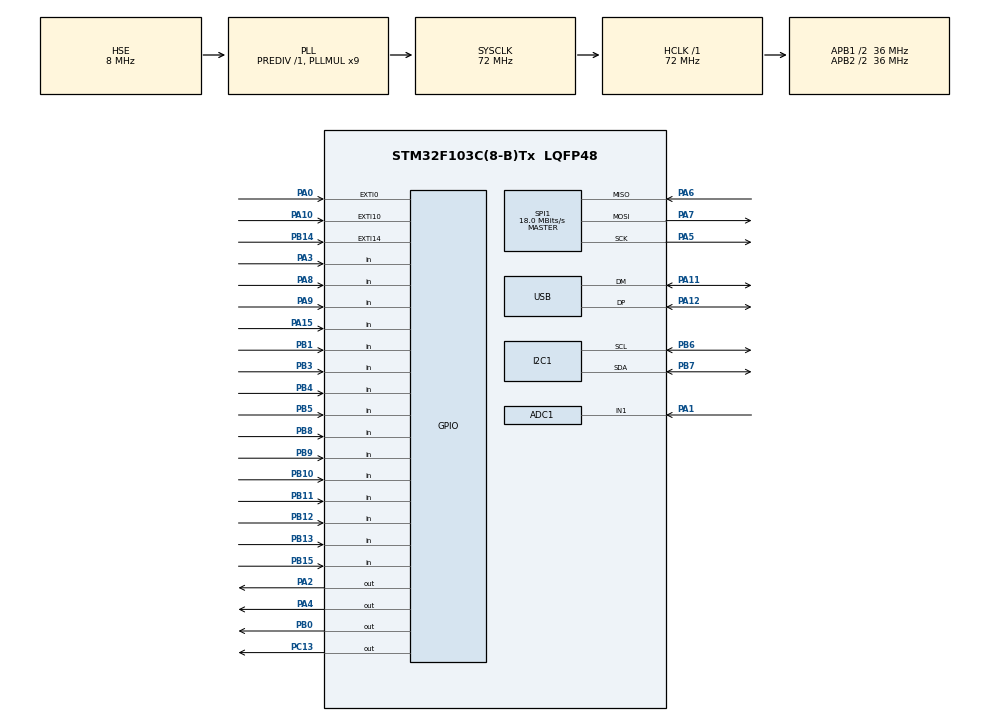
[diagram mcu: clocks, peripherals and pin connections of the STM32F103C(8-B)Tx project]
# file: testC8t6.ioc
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ADC1.Channel-0\#ChannelRegularConversion=ADC_CHANNEL_1
ADC1.NbrOfConversionFlag=1
ADC1.Rank-0\#ChannelRegularConversion=1
ADC1.SamplingTime-0\#ChannelRegularConversion=ADC_SAMPLETIME_1CYCLE_5
ADC1.master=1
Mcu.Family=STM32F1
Mcu.Name=STM32F103C(8-B)Tx
Mcu.Package=LQFP48
NVIC.EXTI15_10_IRQn=true\:9\:0\:true\:false\:true\:true\:true
NVIC.PriorityGroup=NVIC_PRIORITYGROUP_4
NVIC.RCC_IRQn=true\:0\:0\:false\:false\:true\:true\:false
NVIC.TIM3_IRQn=true\:11\:0\:true\:false\:true\:true\:true
NVIC.TIM4_IRQn=true\:0\:0\:false\:false\:true\:true\:true
NVIC.USB_LP_CAN1_RX0_IRQn=true\:0\:0\:false\:false\:true\:false\:true
PA0-WKUP.GPIO_ModeDefaultEXTI=GPIO_MODE_IT_RISING_FALLING
PA0-WKUP.GPIO_PuPd=GPIO_PULLDOWN
PA0-WKUP.Signal=GPXTI0
PA1.Signal=ADCx_IN1
PA10.GPIO_ModeDefaultEXTI=GPIO_MODE_IT_FALLING
PA10.GPIO_PuPd=GPIO_PULLUP
PA10.Signal=GPXTI10
PA11.Mode=Device
PA11.Signal=USB_DM
PA12.Mode=Device
PA12.Signal=USB_DP
PA13.Mode=Serial_Wire
PA13.Signal=SYS_JTMS-SWDIO
PA14.Mode=Serial_Wire
PA14.Signal=SYS_JTCK-SWCLK
PA15.GPIO_PuPd=GPIO_PULLUP
PA15.Signal=GPIO_Input
PA2.Signal=GPIO_Output
PA3.GPIO_PuPd=GPIO_PULLUP
PA3.Signal=GPIO_Input
PA4.GPIO_Speed=GPIO_SPEED_FREQ_HIGH
PA4.Signal=GPIO_Output
PA5.Mode=Full_Duplex_Master
PA5.Signal=SPI1_SCK
PA6.Mode=Full_Duplex_Master
PA6.Signal=SPI1_MISO
PA7.Mode=Full_Duplex_Master
PA7.Signal=SPI1_MOSI
PA8.GPIO_PuPd=GPIO_PULLUP
PA8.Signal=GPIO_Input
PA9.GPIO_PuPd=GPIO_PULLUP
PA9.Signal=GPIO_Input
PB0.Signal=GPIO_Output
PB1.GPIO_PuPd=GPIO_PULLUP
PB1.Signal=GPIO_Input
PB10.GPIO_PuPd=GPIO_PULLUP
PB10.Signal=GPIO_Input
PB11.GPIO_PuPd=GPIO_PULLUP
PB11.Signal=GPIO_Input
PB12.GPIO_PuPd=GPIO_PULLUP
PB12.Signal=GPIO_Input
PB13.GPIO_PuPd=GPIO_PULLUP
PB13.Signal=GPIO_Input
PB14.GPIO_ModeDefaultEXTI=GPIO_MODE_IT_FALLING
PB14.GPIO_PuPd=GPIO_PULLUP
PB14.Signal=GPXTI14
PB15.GPIO_PuPd=GPIO_PULLUP
PB15.Signal=GPIO_Input
PB3.GPIO_PuPd=GPIO_PULLUP
PB3.Signal=GPIO_Input
PB4.GPIO_PuPd=GPIO_PULLUP
PB4.Signal=GPIO_Input
PB5.GPIO_PuPd=GPIO_PULLUP
PB5.Signal=GPIO_Input
PB6.Mode=I2C
PB6.Signal=I2C1_SCL
PB7.Mode=I2C
PB7.Signal=I2C1_SDA
PB8.GPIO_PuPd=GPIO_PULLUP
PB8.Signal=GPIO_Input
PB9.GPIO_PuPd=GPIO_PULLUP
PB9.Signal=GPIO_Input
PC13-TAMPER-RTC.Signal=GPIO_Output
PC14-OSC32_IN.Mode=LSE-External-Oscillator
PC14-OSC32_IN.Signal=RCC_OSC32_IN
PC15-OSC32_OUT.Mode=LSE-External-Oscillator
PC15-OSC32_OUT.Signal=RCC_OSC32_OUT
PD0-OSC_IN.Mode=HSE-External-Oscillator
PD0-OSC_IN.Signal=RCC_OSC_IN
PD1-OSC_OUT.Mode=HSE-External-Oscillator
PD1-OSC_OUT.Signal=RCC_OSC_OUT
ProjectManager.HeapSize=0x400
ProjectManager.StackSize=0x800
ProjectManager.TargetToolchain=MDK-ARM V5.32
RCC.ADCPresc=RCC_ADCPCLK2_DIV6
RCC.AHBFreq_Value=72000000
RCC.APB1CLKDivider=RCC_HCLK_DIV2
RCC.APB1Freq_Value=36000000
RCC.APB1TimFreq_Value=72000000
RCC.APB2CLKDivider=RCC_HCLK_DIV2
RCC.APB2Freq_Value=36000000
RCC.APB2TimFreq_Value=72000000
RCC.HCLKFreq_Value=72000000
RCC.PLLMUL=RCC_PLL_MUL9
RCC.SYSCLKFreq_VALUE=72000000
RCC.SYSCLKSource=RCC_SYSCLKSOURCE_PLLCLK
RCC.USBFreq_Value=48000000
RCC.USBPrescaler=RCC_USBCLKSOURCE_PLL_DIV1_5
SH.ADCx_IN1.0=ADC1_IN1,IN1
SPI1.BaudRatePrescaler=SPI_BAUDRATEPRESCALER_2
SPI1.CalculateBaudRate=18.0 MBits/s
SPI1.Direction=SPI_DIRECTION_2LINES
SPI1.Mode=SPI_MODE_MASTER
SPI1.VirtualType=VM_MASTER
TIM3.AutoReloadPreload=TIM_AUTORELOAD_PRELOAD_ENABLE
TIM3.Period=999
TIM3.Prescaler=71
TIM4.AutoReloadPreload=TIM_AUTORELOAD_PRELOAD_ENABLE
TIM4.Period=9999
TIM4.Prescaler=7199
USB_DEVICE.CLASS_NAME_FS=HID
USB_DEVICE.HID_FS_BINTERVAL=0x1
USB_DEVICE.MANUFACTURER_STRING=CUST114
USB_DEVICE.PID_HID_FS=22315
USB_DEVICE.PRODUCT_STRING_HID_FS=SDVXKey
USB_DEVICE.VID=1156
USB_DEVICE.VirtualMode=Hid
USB_DEVICE.VirtualModeFS=Hid_FS
VP_TIM3_VS_ClockSourceINT.Mode=Internal
VP_TIM4_VS_ClockSourceINT.Mode=Internal
VP_USB_DEVICE_VS_USB_DEVICE_HID_FS.Mode=HID_FS
board=custom

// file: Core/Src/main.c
/* USER CODE BEGIN Header */
/**
  ******************************************************************************
  * @file           : main.c
  * @brief          : Main program body
  ******************************************************************************
  * @attention
  *
  * <h2><center>&copy; Copyright (c) 2021 STMicroelectronics.
  * All rights reserved.</center></h2>
  *
  * This software component is licensed by ST under Ultimate Liberty license
  * SLA0044, the "License"; You may not use this file except in compliance with
  * the License. You may obtain a copy of the License at:
  *                             www.st.com/SLA0044
  *
  ******************************************************************************
  */
/* USER CODE END Header */
#include "main.h"
#include "adc.h"
#include "i2c.h"
#include "spi.h"
#include "tim.h"
#include "usb_device.h"
#include "gpio.h"

/* USER CODE BEGIN Includes */
#include "sdvx_hid.h"
/* USER CODE END Includes */

void SystemClock_Config(void);

/* USER CODE BEGIN 0 */
/*
int fputc(int c, FILE *stream) //重写fputc函数
{
  HAL_UART_Transmit(&huart1, (unsigned char *)&c, 1, 1000);
  return 1;
}
*/
/* USER CODE END 0 */

int main(void)
{

  /* MCU Configuration--------------------------------------------------------*/

  /* Reset of all peripherals, Initializes the Flash interface and the Systick. */
  HAL_Init();

  /* Configure the system clock */
  SystemClock_Config();

  /* Initialize all configured peripherals */
  MX_GPIO_Init();
  MX_USB_DEVICE_Init();
  MX_ADC1_Init();
  MX_I2C1_Init();
  MX_SPI1_Init();
  MX_TIM3_Init();
  MX_TIM4_Init();
  /* USER CODE BEGIN 2 */
  HAL_TIM_Base_Start_IT(&htim3);
  HAL_TIM_Base_Start_IT(&htim4);
  //uint8_t MouseData[4] = {0,0,0,0};

  //initSDVX();
  /* USER CODE END 2 */

  /* Infinite loop */
  while (1)
  {

    /* USER CODE BEGIN 3 */
    //KMouseData[MoveY] = 0;
    listenSDVXData();

    //HAL_Delay(hid);
  }
  /* USER CODE END 3 */
}

void SystemClock_Config(void)
{
  RCC_OscInitTypeDef RCC_OscInitStruct = {0};
  RCC_ClkInitTypeDef RCC_ClkInitStruct = {0};
  RCC_PeriphCLKInitTypeDef PeriphClkInit = {0};

  /** Initializes the RCC Oscillators according to the specified parameters
  * in the RCC_OscInitTypeDef structure.
  */
  RCC_OscInitStruct.OscillatorType = RCC_OSCILLATORTYPE_HSE;
  RCC_OscInitStruct.HSEState = RCC_HSE_ON;
  RCC_OscInitStruct.HSEPredivValue = RCC_HSE_PREDIV_DIV1;
  RCC_OscInitStruct.HSIState = RCC_HSI_ON;
  RCC_OscInitStruct.PLL.PLLState = RCC_PLL_ON;
  RCC_OscInitStruct.PLL.PLLSource = RCC_PLLSOURCE_HSE;
  RCC_OscInitStruct.PLL.PLLMUL = RCC_PLL_MUL9;
  if (HAL_RCC_OscConfig(&RCC_OscInitStruct) != HAL_OK)
  {
    Error_Handler();
  }
  /** Initializes the CPU, AHB and APB buses clocks
  */
  RCC_ClkInitStruct.ClockType = RCC_CLOCKTYPE_HCLK|RCC_CLOCKTYPE_SYSCLK
                              |RCC_CLOCKTYPE_PCLK1|RCC_CLOCKTYPE_PCLK2;
  RCC_ClkInitStruct.SYSCLKSource = RCC_SYSCLKSOURCE_PLLCLK;
  RCC_ClkInitStruct.AHBCLKDivider = RCC_SYSCLK_DIV1;
  RCC_ClkInitStruct.APB1CLKDivider = RCC_HCLK_DIV2;
  RCC_ClkInitStruct.APB2CLKDivider = RCC_HCLK_DIV2;

  if (HAL_RCC_ClockConfig(&RCC_ClkInitStruct, FLASH_LATENCY_2) != HAL_OK)
  {
    Error_Handler();
  }
  PeriphClkInit.PeriphClockSelection = RCC_PERIPHCLK_ADC|RCC_PERIPHCLK_USB;
  PeriphClkInit.AdcClockSelection = RCC_ADCPCLK2_DIV6;
  PeriphClkInit.UsbClockSelection = RCC_USBCLKSOURCE_PLL_DIV1_5;
  if (HAL_RCCEx_PeriphCLKConfig(&PeriphClkInit) != HAL_OK)
  {
    Error_Handler();
  }
}

void Error_Handler(void)
{
  __disable_irq();
  while (1)
  {
  }
}

/************************ (C) COPYRIGHT STMicroelectronics *****END OF FILE****/
